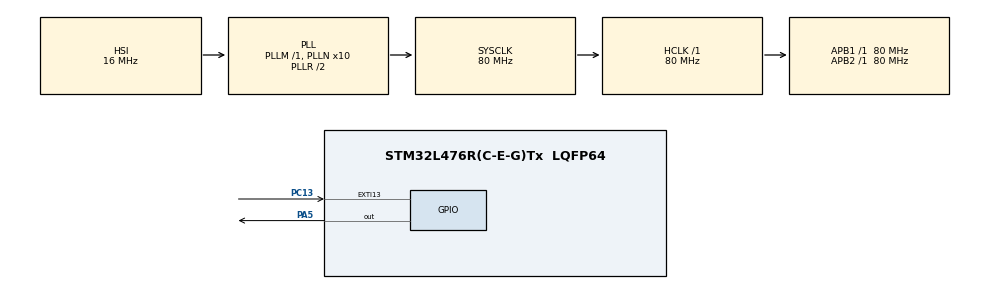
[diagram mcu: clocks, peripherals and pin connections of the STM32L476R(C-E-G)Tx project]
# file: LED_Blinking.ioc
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Mcu.Family=STM32L4
Mcu.Name=STM32L476R(C-E-G)Tx
Mcu.Package=LQFP64
NVIC.EXTI15_10_IRQn=true\:0\:0\:false\:false\:true
NVIC.PriorityGroup=NVIC_PRIORITYGROUP_4
NVIC.RCC_IRQn=true\:0\:0\:false\:false\:true
PA5.Signal=GPIO_Output
PC13.Signal=GPXTI13
PH0/OSC_IN.Mode=HSE-External-Oscillator
PH0/OSC_IN.Signal=RCC_OSC_IN
PH1/OSC_OUT.Mode=HSE-External-Oscillator
PH1/OSC_OUT.Signal=RCC_OSC_OUT
ProjectManager.HeapSize=0x200
ProjectManager.StackSize=0x400
ProjectManager.TargetToolchain=EWARM
RCC.ADCFreq_Value=64000000
RCC.AHBFreq_Value=80000000
RCC.APB1Freq_Value=80000000
RCC.APB1TimFreq_Value=80000000
RCC.APB2Freq_Value=80000000
RCC.APB2TimFreq_Value=80000000
RCC.CortexFreq_Value=80000000
RCC.HCLKFreq_Value=80000000
RCC.HSE_VALUE=8000000
RCC.HSI_VALUE=16000000
RCC.LSE_VALUE=32768
RCC.MSI_VALUE=4000000
RCC.PLLN=10
RCC.PLLSourceVirtual=RCC_PLLSOURCE_HSI
RCC.PREFETCH_ENABLE=1
RCC.SYSCLKFreq_VALUE=80000000
RCC.SYSCLKSource=RCC_SYSCLKSOURCE_PLLCLK
RCC.USBFreq_Value=64000000
RCC.VCOOutputFreq_Value=160000000
board=NUCLEO-L476RG

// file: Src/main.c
/**
  ******************************************************************************
  * File Name          : main.c
  * Description        : Main program body
  ******************************************************************************
  *
  * COPYRIGHT(c) 2017 STMicroelectronics
  *
  * Redistribution and use in source and binary forms, with or without modification,
  * are permitted provided that the following conditions are met:
  *   1. Redistributions of source code must retain the above copyright notice,
  *      this list of conditions and the following disclaimer.
  *   2. Redistributions in binary form must reproduce the above copyright notice,
  *      this list of conditions and the following disclaimer in the documentation
  *      and/or other materials provided with the distribution.
  *   3. Neither the name of STMicroelectronics nor the names of its contributors
  *      may be used to endorse or promote products derived from this software
  *      without specific prior written permission.
  *
  * THIS SOFTWARE IS PROVIDED BY THE COPYRIGHT HOLDERS AND CONTRIBUTORS "AS IS"
  * AND ANY EXPRESS OR IMPLIED WARRANTIES, INCLUDING, BUT NOT LIMITED TO, THE
  * IMPLIED WARRANTIES OF MERCHANTABILITY AND FITNESS FOR A PARTICULAR PURPOSE ARE
  * DISCLAIMED. IN NO EVENT SHALL THE COPYRIGHT HOLDER OR CONTRIBUTORS BE LIABLE
  * FOR ANY DIRECT, INDIRECT, INCIDENTAL, SPECIAL, EXEMPLARY, OR CONSEQUENTIAL
  * DAMAGES (INCLUDING, BUT NOT LIMITED TO, PROCUREMENT OF SUBSTITUTE GOODS OR
  * SERVICES; LOSS OF USE, DATA, OR PROFITS; OR BUSINESS INTERRUPTION) HOWEVER
  * CAUSED AND ON ANY THEORY OF LIABILITY, WHETHER IN CONTRACT, STRICT LIABILITY,
  * OR TORT (INCLUDING NEGLIGENCE OR OTHERWISE) ARISING IN ANY WAY OUT OF THE USE
  * OF THIS SOFTWARE, EVEN IF ADVISED OF THE POSSIBILITY OF SUCH DAMAGE.
  *
  ******************************************************************************
  */
#include "main.h"
#include "stm32l4xx_hal.h"

/* USER CODE BEGIN PV */
/* Private variables ---------------------------------------------------------*/
  uint16_t tDelay = 100; // variable non-signée sur 2 octets "tDelay" initialiser à 100 pour communiquer en milliseconde le clignotement de la led
/* USER CODE END PV */

void SystemClock_Config(void); //code généré automatiquement via la configuration sur stmCube avec le RCC Reset and Clock Control
void Error_Handler(void); //code généré automatiquement via la configuration sur stmCube
static void MX_GPIO_Init(void); //code généré automatiquement via la configuration sur stmCube

/* USER CODE BEGIN PFP */
/* Private function prototypes -----------------------------------------------*/

/* USER CODE END PFP */

int main(void)
{

  /* MCU Configuration----------------------------------------------------------*/

  /* Reset of all peripherals, Initializes the Flash interface and the Systick. */
  HAL_Init();

  /* Configure the system clock */
  SystemClock_Config();

  /* Initialize all configured peripherals */
  MX_GPIO_Init();

  /* Infinite loop */
  /* USER CODE BEGIN WHILE */
  while (1) // Boucle infini pour le clignotemment de la LED
  {
  /* USER CODE END WHILE */

  /* USER CODE BEGIN 3 */
    HAL_GPIO_TogglePin(GPIOA, GPIO_PIN_5); // GPIO_PIN_5, 5 correspond ale LED qui est la Pin PA5 dans les configurations stmCube configurer auparavant. GPIOA, traite l'interuption avec evenements
    HAL_Delay(tDelay);// Initialiser la fonction HAL_Delay avec la variable tDelay pour recevoir la valeur de la variable pour le clignotement

  }
  /* USER CODE END 3 */

}

/** System Clock Configuration
*/
void SystemClock_Config(void)
{

  RCC_OscInitTypeDef RCC_OscInitStruct;
  RCC_ClkInitTypeDef RCC_ClkInitStruct;

    /**Initializes the CPU, AHB and APB busses clocks
    */
  RCC_OscInitStruct.OscillatorType = RCC_OSCILLATORTYPE_HSI;
  RCC_OscInitStruct.HSIState = RCC_HSI_ON;
  RCC_OscInitStruct.HSICalibrationValue = 16;
  RCC_OscInitStruct.PLL.PLLState = RCC_PLL_ON;
  RCC_OscInitStruct.PLL.PLLSource = RCC_PLLSOURCE_HSI;
  RCC_OscInitStruct.PLL.PLLM = 1;
  RCC_OscInitStruct.PLL.PLLN = 10;
  RCC_OscInitStruct.PLL.PLLP = RCC_PLLP_DIV7;
  RCC_OscInitStruct.PLL.PLLQ = RCC_PLLQ_DIV2;
  RCC_OscInitStruct.PLL.PLLR = RCC_PLLR_DIV2;
  if (HAL_RCC_OscConfig(&RCC_OscInitStruct) != HAL_OK)
  {
    Error_Handler();
  }

    /**Initializes the CPU, AHB and APB busses clocks
    */
  RCC_ClkInitStruct.ClockType = RCC_CLOCKTYPE_HCLK|RCC_CLOCKTYPE_SYSCLK
                              |RCC_CLOCKTYPE_PCLK1|RCC_CLOCKTYPE_PCLK2;
  RCC_ClkInitStruct.SYSCLKSource = RCC_SYSCLKSOURCE_PLLCLK;
  RCC_ClkInitStruct.AHBCLKDivider = RCC_SYSCLK_DIV1;
  RCC_ClkInitStruct.APB1CLKDivider = RCC_HCLK_DIV1;
  RCC_ClkInitStruct.APB2CLKDivider = RCC_HCLK_DIV1;

  if (HAL_RCC_ClockConfig(&RCC_ClkInitStruct, FLASH_LATENCY_4) != HAL_OK)
  {
    Error_Handler();
  }

    /**Configure the main internal regulator output voltage
    */
  if (HAL_PWREx_ControlVoltageScaling(PWR_REGULATOR_VOLTAGE_SCALE1) != HAL_OK)
  {
    Error_Handler();
  }

    /**Configure the Systick interrupt time
    */
  HAL_SYSTICK_Config(HAL_RCC_GetHCLKFreq()/1000);

    /**Configure the Systick
    */
  HAL_SYSTICK_CLKSourceConfig(SYSTICK_CLKSOURCE_HCLK);

  /* SysTick_IRQn interrupt configuration */
  HAL_NVIC_SetPriority(SysTick_IRQn, 0, 0);
}

/** Configure pins as
        * Analog
        * Input
        * Output
        * EVENT_OUT
        * EXTI
*/
static void MX_GPIO_Init(void)
{

  GPIO_InitTypeDef GPIO_InitStruct;

  /* GPIO Ports Clock Enable */
  __HAL_RCC_GPIOC_CLK_ENABLE();
  __HAL_RCC_GPIOH_CLK_ENABLE();
  __HAL_RCC_GPIOA_CLK_ENABLE();

  /*Configure GPIO pin Output Level */
  HAL_GPIO_WritePin(GPIOA, GPIO_PIN_5, GPIO_PIN_RESET);

  /*Configure GPIO pin : PC13 */
  GPIO_InitStruct.Pin = GPIO_PIN_13;
  GPIO_InitStruct.Mode = GPIO_MODE_IT_RISING;
  GPIO_InitStruct.Pull = GPIO_NOPULL;
  HAL_GPIO_Init(GPIOC, &GPIO_InitStruct);

  /*Configure GPIO pin : PA5 */
  GPIO_InitStruct.Pin = GPIO_PIN_5;
  GPIO_InitStruct.Mode = GPIO_MODE_OUTPUT_PP;
  GPIO_InitStruct.Pull = GPIO_NOPULL;
  GPIO_InitStruct.Speed = GPIO_SPEED_FREQ_LOW;
  HAL_GPIO_Init(GPIOA, &GPIO_InitStruct);

  /* EXTI interrupt init*/
  HAL_NVIC_SetPriority(EXTI15_10_IRQn, 0, 0);
  HAL_NVIC_EnableIRQ(EXTI15_10_IRQn);

}

void Error_Handler(void)
{
  while(1)
  {
  }
}

/************************ (C) COPYRIGHT STMicroelectronics *****END OF FILE****/
